# CM_CORE_AON__DSP1 register map
Vendor: Texas Instruments
Peripheral module from a debugger description file (folder TDA2Px).
Registers are 32-bit, access per field, reset 0x3 unless marked. A register's access mark holds for its fields unless they carry their own. Offsets are as the file gives them; lines under a group give offsets from that group; [hi:lo] are bit positions; {n}, {i} and the like mark numbered series; 'fields as' and 'values as' point back to an identical list; <NAME> marks a mode.

## CM_CORE_AON__DSP1
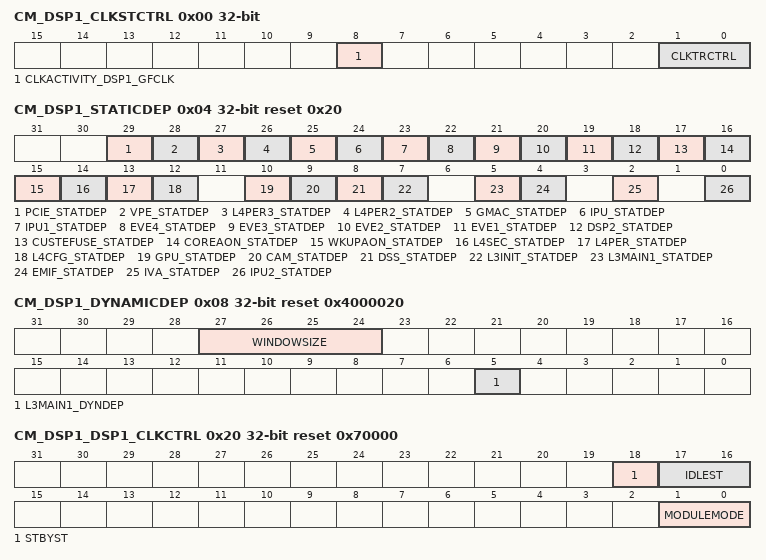
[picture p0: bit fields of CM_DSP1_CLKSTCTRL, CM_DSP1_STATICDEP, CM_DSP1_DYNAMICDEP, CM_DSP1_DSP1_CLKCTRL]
0x00 CM_DSP1_CLKSTCTRL — This register enables the DSP domain power state transition. It controls the HW supervised domain power state transition between ON-ACTIVE and ON-INACTIVE states. It also hold one status bit per clock input of the domain.
  [8] CLKACTIVITY_DSP1_GFCLK ro — This field indicates the state of the DSP_ROOT_CLK clock in the domain. [warm reset insensitive]
    0=INACT (Corresponding clock is definitely gated); 1=ACT (Corresponding clock is running or gating/ungating transition is on-going)
  [1:0] CLKTRCTRL rw — Controls the clock state transition of the DSP clock domain.
    0=NO_SLEEP (NO_SLEEP: Sleep transition cannot be initiated. Wakeup transition may however occur.); 1=SW_SLEEP (SW_SLEEP: Start a software forced sleep transition on the domain.); 2=SW_WKUP (SW_WKUP: Start a software forced wake-up transition on the domain.); 3=HW_AUTO (HW_AUTO: Automatic transition is enabled. Sleep and wakeup transition are based upon hardware conditions.)
0x04 CM_DSP1_STATICDEP reset 0x20 — This register controls the static domain depedencies from DSP domain towards 'target' domains. It is relevant only for domain having system initiator(s).
  [29] PCIE_STATDEP rw — Static dependency towards PCIE Clock Domain
    0=DISABLED (Dependency is disabled); 1=ENABLED (Dependency is enabled)
  [28] VPE_STATDEP rw — Static dependency towards VPE Clock Domain
    0=Dependency_is_disabled; 1=Dependency_is_enabled
  [27] L4PER3_STATDEP rw — Static dependency towards L4PER3 Clock Domain
    values as PCIE_STATDEP
  [26] L4PER2_STATDEP rw — Static dependency towards L4PER2 Clock Domain
    values as PCIE_STATDEP
  [25] GMAC_STATDEP rw — Static dependency towards GMAC Clock Domain
    values as PCIE_STATDEP
  [24] IPU_STATDEP rw — Static dependency towards IPU Clock Domain
    values as PCIE_STATDEP
  [23] IPU1_STATDEP rw — Static dependency towards IPU1 Clock Domain
    values as PCIE_STATDEP
  [22] EVE4_STATDEP rw — Static dependency towards EVE4 Clock DomainEVE4 is not supported in this family of devices.
    values as PCIE_STATDEP
  [21] EVE3_STATDEP rw — Static dependency towards EVE3 Clock DomainEVE3 is not supported in this family of devices.
    values as PCIE_STATDEP
  [20] EVE2_STATDEP rw — Static dependency towards EVE2 Clock Domain
    values as PCIE_STATDEP
  [19] EVE1_STATDEP rw — Static dependency towards EVE1 Clock Domain
    values as PCIE_STATDEP
  [18] DSP2_STATDEP rw — Static dependency towards DSP2 Clock Domain
    values as PCIE_STATDEP
  [17] CUSTEFUSE_STATDEP ro — Static dependency towards CUSTEFUSE Clock Domain
    0=DISABLED (Dependency is disabled)
  [16] COREAON_STATDEP ro — Static dependency towards COREAON Clock Domain
    0=DISABLED (Dependency is disabled)
  [15] WKUPAON_STATDEP rw — Static dependency towards WKUPAON Clock Domain
    values as PCIE_STATDEP
  [14] L4SEC_STATDEP rw — Static dependency towards L4SEC Clock Domain
    values as PCIE_STATDEP
  [13] L4PER_STATDEP rw — Static dependency towards L4PER1Clock Domain
    values as PCIE_STATDEP
  [12] L4CFG_STATDEP ro — Static dependency towards L4CFG Clock Domain
    0=DISABLED (Dependency is disabled)
  [10] GPU_STATDEP rw — Static dependency towards GPU Clock Domain
    values as PCIE_STATDEP
  [9] CAM_STATDEP rw — Static dependency towards CAM Clock Domain
    values as PCIE_STATDEP
  [8] DSS_STATDEP rw — Static dependency towards DSS Clock Domain
    values as PCIE_STATDEP
  [7] L3INIT_STATDEP rw — Static dependency towards L3INIT Clock Domain
    values as PCIE_STATDEP
  [5] L3MAIN1_STATDEP ro — Static dependency towards L3MAIN1 Clock Domain
    1=ENABLED (Dependency is enabled)
  [4] EMIF_STATDEP rw — Static dependency towards EMIF Clock Domain
    values as PCIE_STATDEP
  [2] IVA_STATDEP rw — Static dependency towards IVA Clock Domain
    values as PCIE_STATDEP
  [0] IPU2_STATDEP rw — Static dependency towards IPU2 Clock Domain
    0=Dependency_is_disabled; 1=Dependency_is_enabled
0x08 CM_DSP1_DYNAMICDEP reset 0x4000020 — This register controls the dynamic domain depedencies from DSP domain towards 'target' domains. It is relevant only for domain having OCP master port(s).
  [27:24] WINDOWSIZE rw — Size of sliding window used to monitor OCP interface activity for determination of auto-sleep feature. Time unit defined byCM_DYN_DEP_PRESCAL register.
  [5] L3MAIN1_DYNDEP ro — Dynamic dependency towards L3MAIN1 clock domain
    1=ENABLED (Dependency is enabled)
0x20 CM_DSP1_DSP1_CLKCTRL reset 0x70000 — This register manages the DSP clocks.
  [18] STBYST ro — Module standby status. [warm reset insensitive]
    0=FUNC (Module is functional (not in standby)); 1=STANDBY (Module is in standby)
  [17:16] IDLEST ro — Module idle status. [warm reset insensitive]
    0=FUNC (Module is fully functional, including OCP); 1=TRANS (Module is performing transition: wakeup, or sleep, or sleep abortion); 2=IDLE (Module is in Idle mode (only OCP part). It is functional if using separate functional clock); 3=DISABLE (Module is disabled and cannot be accessed)
  [1:0] MODULEMODE rw — Control the way mandatory clocks are managed.
    0=DISABLED (Module is disabled by SW. Any OCP access to module results in an error, except if resulting from a module wakeup (asynchronous wakeup).); 1=AUTO (Module is managed automatically by HW according to clock domain transition. A clock domain sleep transition put module into idle. A wakeup domain transition put it back into function. If CLKTRCTRL=3, any OCP access to module is always granted. Module clocks may be gated according to the clock domain state.)
